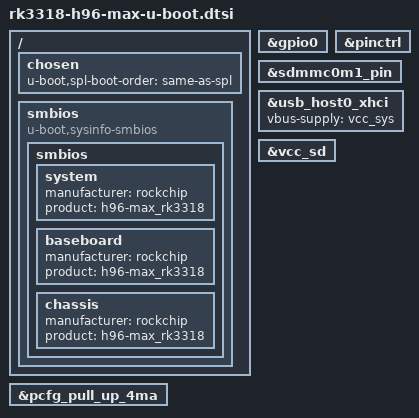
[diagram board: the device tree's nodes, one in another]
// SPDX-License-Identifier: GPL-2.0+
/*
 * (C) Copyright 2018-2019 Rockchip Electronics Co., Ltd
 */

#include "rk3328-u-boot.dtsi"
#include "rk3328-sdram-ddr3-666.dtsi"
/ {
	chosen {
		u-boot,spl-boot-order = "same-as-spl", &sdmmc, &emmc;
		};

	smbios {
		compatible = "u-boot,sysinfo-smbios";

		smbios {
			system {
				manufacturer = "rockchip";
				product = "h96-max_rk3318";
			};

			baseboard {
				manufacturer = "rockchip";
				product = "h96-max_rk3318";
			};

			chassis {
				manufacturer = "rockchip";
				product = "h96-max_rk3318";
			};
		};
	};
};

&gpio0 {
	u-boot,dm-spl;
};

&pinctrl {
	u-boot,dm-spl;
};

&sdmmc0m1_pin {
	u-boot,dm-spl;
};

&pcfg_pull_up_4ma {
	u-boot,dm-spl;
};

&usb_host0_xhci {
	vbus-supply = <&vcc_sys>;
	status = "okay";
};

/* Need this and all the pinctrl/gpio stuff above to set pinmux */
&vcc_sd {
	u-boot,dm-spl;
};

